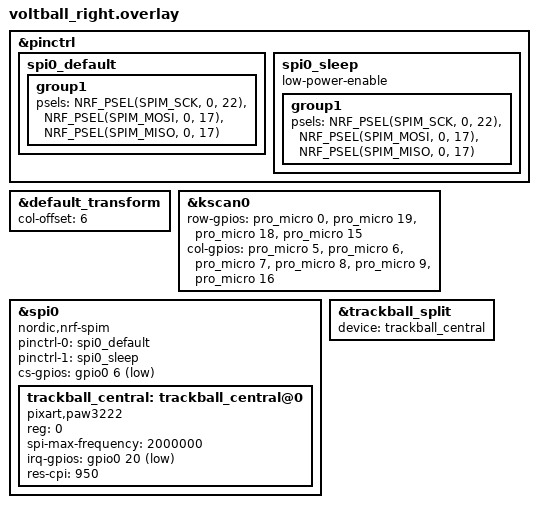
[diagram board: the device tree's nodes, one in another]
#include "voltball.dtsi"
#include "voltball-split-input.dtsi"
#include <zephyr/dt-bindings/gpio/nordic-nrf-gpio.h>

&pinctrl {
    spi0_default: spi0_default {
        group1 {
            psels = <NRF_PSEL(SPIM_SCK, 0, 22)>,
                    <NRF_PSEL(SPIM_MOSI, 0, 17)>,
                    <NRF_PSEL(SPIM_MISO, 0, 17)>;
        };
    };

    spi0_sleep: spi0_sleep {
        group1 {
            psels = <NRF_PSEL(SPIM_SCK, 0, 22)>,
                    <NRF_PSEL(SPIM_MOSI, 0, 17)>,
                    <NRF_PSEL(SPIM_MISO, 0, 17)>;
        };
        low-power-enable;
    };
};

&default_transform {
    col-offset = <6>;
};

&kscan0 {
    row-gpios
        = <&pro_micro 0 (GPIO_ACTIVE_HIGH | GPIO_PULL_DOWN)>
        , <&pro_micro 19 (GPIO_ACTIVE_HIGH | GPIO_PULL_DOWN)>
        , <&pro_micro 18 (GPIO_ACTIVE_HIGH | GPIO_PULL_DOWN)>
        , <&pro_micro 15 (GPIO_ACTIVE_HIGH | GPIO_PULL_DOWN)>
        ;

    col-gpios
        = <&pro_micro 5 GPIO_ACTIVE_HIGH>
        , <&pro_micro 6 GPIO_ACTIVE_HIGH>
        , <&pro_micro 7 GPIO_ACTIVE_HIGH>
        , <&pro_micro 8 GPIO_ACTIVE_HIGH>
        , <&pro_micro 9 GPIO_ACTIVE_HIGH>
        , <&pro_micro 16 GPIO_ACTIVE_HIGH>
        ;
};

&spi0 {
    status = "okay";
    compatible = "nordic,nrf-spim";
    pinctrl-0 = <&spi0_default>;
    pinctrl-1 = <&spi0_sleep>;
    pinctrl-names = "default", "sleep";
    cs-gpios = <&gpio0 6 GPIO_ACTIVE_LOW>;

    trackball_central: trackball_central@0 {
        status = "okay";
        compatible = "pixart,paw3222";
        reg = <0>;
        spi-max-frequency = <2000000>;
        irq-gpios = <&gpio0 20 (GPIO_ACTIVE_LOW | GPIO_PULL_UP)>;
        /*
         * 中文: 驱动未配置 res-cpi 时会保留 PAW3222 传感器硬件默认值。
         * English: Without res-cpi, the driver keeps the PAW3222 sensor hardware default.
         *
         * 中文: 当前驱动有效范围是 608-4826 CPI，步进为 38；建议使用 38 的整数倍。
         * English: This driver accepts 608-4826 CPI in steps of 38; prefer multiples of 38.
         *
         * 中文: 常用值: 608, 760, 950, 1140, 1520, 1900, 2280, 2660, 3040, 3420, 3800, 4180, 4560, 4826。
         * English: Common values: 608, 760, 950, 1140, 1520, 1900, 2280, 2660, 3040, 3420, 3800, 4180, 4560, 4826.
         */
        res-cpi = <950>;
    };
};


&trackball_split { device = <&trackball_central>; };
